# MDR32F8 register map
Vendor: Milandr; File version: 1.0
CPU: CM4 r1p1, little endian, no MPU, FPU, 3 interrupt priority bits
Registers are 32-bit, read-write, reset 0x0 unless marked. A register's access mark holds for its fields unless they carry their own. Offsets are from the block's base; lines under a group give offsets from that group; [hi:lo] are bit positions; {n}, {i} and the like mark numbered series; 'fields as' and 'values as' point back to an identical list; <NAME> marks a mode.

## Memory map
0x40000000 MDR_CLK size 0x1000 — Clock controll registers
0x40003000 FT_CNTR size 0x88 — Fault Tolerance Control
0x40004000 MDR_WDT size 0x10 — Watch Dog Timer
0x40005000 MDR_EBC size 0x88 — External Bus Control
0x40006000 MDR_OTP size 0x28 — OTP Memory Control
0x40008000 MDR_RAMD size 0x18 — RAMD Control
0x40009000 MDR_ROM size 0x18 — ROM Control
0x4000B000 MDR_SCACHE size 0x30 — S-BUS Cache Controller
0x40010000 MDR_USB size 0x1000 — USB interfase controller registers
0x40018000 MDR_EEPROM size 0x1000 — Flash programm memory interfase controller registers
0x40020000 MDR_RST_CLK size 0x1000 — RST_CLK
0x40080000 MDR_PORTA size 0x8C — PORTA
0x40081000 MDR_PORTB size 0x8C — PORTB
0x40082000 MDR_PORTC size 0x8C — PORTC
0x40083000 MDR_PORTD size 0x8C — PORTD
0x40084000 MDR_PORTE size 0x8C — PORTE
0xE0044000 MDR_ICACHE size 0x30 — I-BUS Cache Controller
0xE0045000 MDR_DCACHE size 0x30 — D-BUS Cache Controller

## Interrupts
2 USB_IRQ (MDR_USB)
32 FT_IF0 (FT_CNTR)
33 FT_IF1 (FT_CNTR)
34 FT_IF2 (FT_CNTR)
35 FT_IF3 (FT_CNTR)
{n+40} EXT_INTERROR{n} (MDR_EBC) (n=0..7)
83 IRQ_PORTA (MDR_PORTA)
84 IRQ_PORTB (MDR_PORTB)
85 IRQ_PORTC (MDR_PORTC)
86 IRQ_PORTD (MDR_PORTD)
87 IRQ_PORTE (MDR_PORTE)

## MDR_USB — USB interfase controller registers
Base 0x40010000; register names take the prefix MDR_USB_
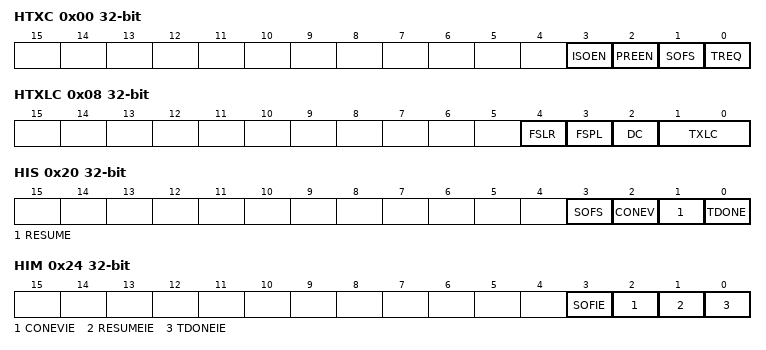
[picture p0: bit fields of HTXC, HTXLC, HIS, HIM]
0x00 HTXC — USB HTXC Register
  [3] ISOEN, [2] PREEN, [1] SOFS, [0] TREQ
0x04 HTXT — USB HTXT Register
  [1:0] TTYPE
0x08 HTXLC — USB HTXLC Register
  [4] FSLR, [3] FSPL, [2] DC, [1:0] TXLC
0x0C HTXSE
  [0] SOFEN
0x10 HTXA
  [6:0] DEVADDR
0x14 HTXE
  [3:0] EPADDR
0x18 HFN_L
  [7:0] FNUM
0x1C HFN_H
  [2:0] FNUM
0x20 HIS — USB_HIS Register
  [3] SOFS, [2] CONEV, [1] RESUME, [0] TDONE
0x24 HIM — USB_HIM Register
  [3] SOFIE, [2] CONEVIE, [1] RESUMEIE, [0] TDONEIE
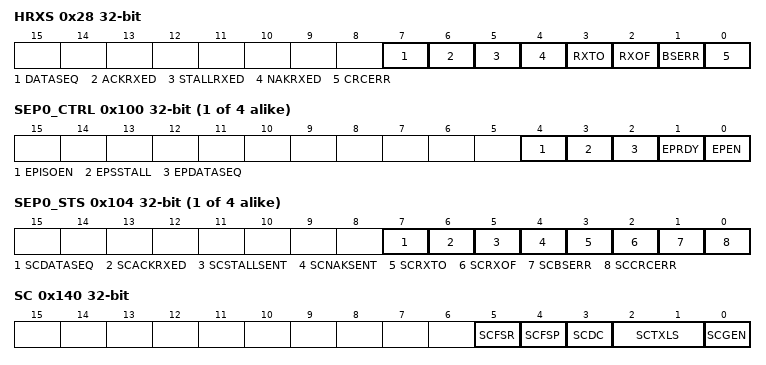
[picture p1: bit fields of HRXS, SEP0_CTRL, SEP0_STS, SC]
0x28 HRXS — USB_HRXS Register
  [7] DATASEQ, [6] ACKRXED, [5] STALLRXED, [4] NAKRXED, [3] RXTO, [2] RXOF, [1] BSERR, [0] CRCERR
0x2C HRXP
  [3:0] RPID
0x30 HRXA
  [6:0] RADDR
0x34 HRXE
  [3:0] RENDP
0x38 HRXCS
  [1:0] RXLS
0x3C HSTM
  [7:0] HSTM
0x80 HRXFD
  [7:0] RXFIFODATA
0x88 HRXFDC_L
  [7:0] FIFODATACOUNT
0x8C HRXFDC_H
  [7:0] FIFODATACOUNT
0x90 HRXFC
  [0] FIFOFORCEEMPTY
0xC0 HTXFD
  [7:0] TXFIFODATA
0xD0 HTXFC
  [0] FIFOFORCEEMPTY
{0x100+0x10*i} SEP{i}_CTRL (i=0..3) — USB_SEP Control Register
  [4] EPISOEN, [3] EPSSTALL, [2] EPDATASEQ, [1] EPRDY, [0] EPEN
{0x104+0x10*i} SEP{i}_STS (i=0..3) — USB_SEP Status Register
  [7] SCDATASEQ, [6] SCACKRXED, [5] SCSTALLSENT, [4] SCNAKSENT, [3] SCRXTO, [2] SCRXOF, [1] SCBSERR, [0] SCCRCERR
{0x108+0x10*i} SEP{i}_TS (i=0..3)
  [1:0] SCTTYPE
{0x10C+0x10*i} SEP{i}_NTS (i=0..3)
  [1:0] NTTYPE
0x140 SC — USB_SC Register
  [5] SCFSR, [4] SCFSP, [3] SCDC, [2:1] SCTXLS, [0] SCGEN
0x144 SLS
  [1:0] SCRXLS
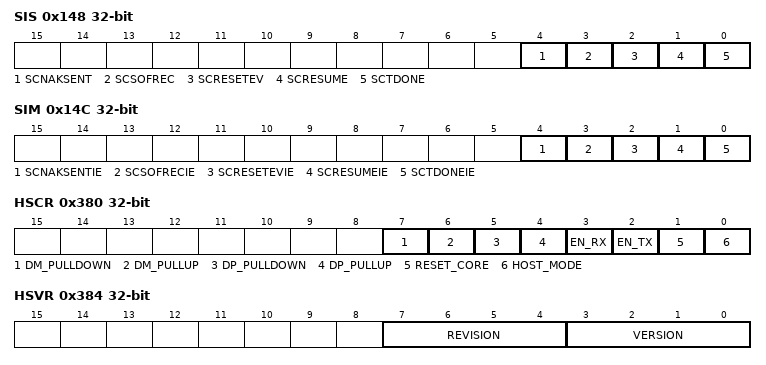
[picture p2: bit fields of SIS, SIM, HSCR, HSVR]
0x148 SIS — USB_SIS Register
  [4] SCNAKSENT, [3] SCSOFREC, [2] SCRESETEV, [1] SCRESUME, [0] SCTDONE
0x14C SIM — USB_SIM Register
  [4] SCNAKSENTIE, [3] SCSOFRECIE, [2] SCRESETEVIE, [1] SCRESUMEIE, [0] SCTDONEIE
0x150 SA
  [6:0] SCDEVADDR
0x154 SFN_L
  [7:0] FRAMENUM
0x158 SFN_H
  [2:0] FRAMENUM
{0x180+0x18*i} SEP_FIFO{i}_RXFD (i=0..3)
  [7:0] RXFIFODATA
{0x188+0x18*i} SEP_FIFO{i}_RXFDC_L (i=0..2)
  [7:0] FIFODATACOUNT
{0x18C+0x18*i} SEP_FIFO{i}_RXFDC_H (i=0..3)
  [7:0] FIFODATACOUNT
0x190 SEP_FIFO0_RXFC
  [0] FIFOFORCEEMPTY
0x1A8 SEP_FIFO1_RXFC
  [0] FIFOFORCEEMPTY
{0x1C0+0x18*i} SEP_FIFO{i}_TXFD (i=0..3)
  [7:0] TXFIFODATA
{0x1D0+0x18*i} SEP_FIFO{i}_TXFDC (i=0..3)
  [0] FIFOFORCEEMPTY
0x290 SEP_FIFO2_RXFC
  [0] FIFOFORCEEMPTY
0x308 SEP_FIFO3_RXFDC_L
  [7:0] FIFODATACOUNT
0x310 SEP_FIFO3_RXFC
  [0] FIFOFORCEEMPTY
0x380 HSCR — USB_HSCR Register
  [7] DM_PULLDOWN, [6] DM_PULLUP, [5] DP_PULLDOWN, [4] DP_PULLUP, [3] EN_RX, [2] EN_TX, [1] RESET_CORE, [0] HOST_MODE
0x384 HSVR — USB_HSVR Register
  [7:4] REVISION, [3:0] VERSION
